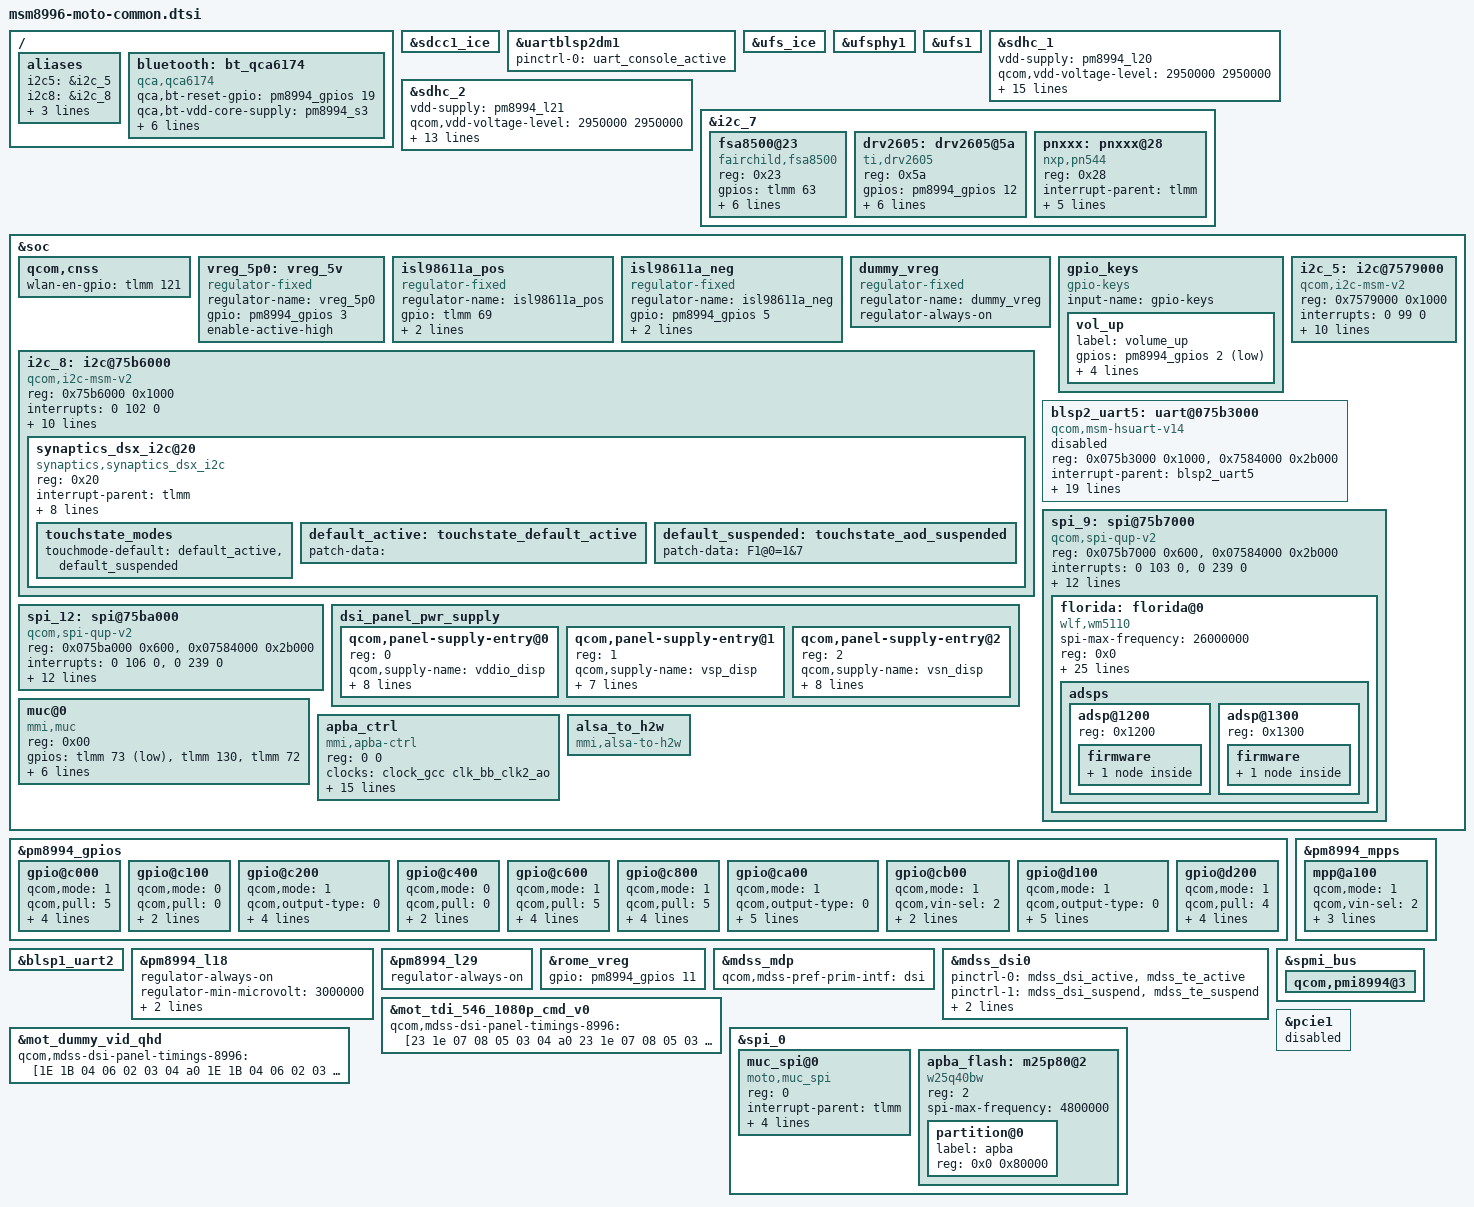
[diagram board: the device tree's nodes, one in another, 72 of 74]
/* Copyright (c) 2015, Motorola Mobility Inc. All rights reserved.
 *
 * This program is free software; you can redistribute it and/or modify
 * it under the terms of the GNU General Public License version 2 and
 * only version 2 as published by the Free Software Foundation.
 *
 * This program is distributed in the hope that it will be useful,
 * but WITHOUT ANY WARRANTY; without even the implied warranty of
 * MERCHANTABILITY or FITNESS FOR A PARTICULAR PURPOSE.  See the
 * GNU General Public License for more details.
 */


#include "msm8996-v2.dtsi"
#include "msm8996-pinctrl.dtsi"
#include "msm8996-moto-pinctrl.dtsi"

&sdcc1_ice {
        status = "ok";
};

/ {
	aliases {
		/delete-property/ i2c12;
		i2c5 = &i2c_5;
		i2c8 = &i2c_8;
		spi9 = &spi_9;
		spi12 = &spi_12;
		uart0 = &blsp1_uart2;
	};
};

&uartblsp2dm1 {
	status = "ok";
	pinctrl-names = "default";
	pinctrl-0 = <&uart_console_active>;
};

&ufs_ice {
	status = "ok";
};

&ufsphy1 {
	status = "ok";
};

&ufs1 {
	status = "ok";
};

&sdhc_1 {
	vdd-supply = <&pm8994_l20>;
	qcom,vdd-voltage-level = <2950000 2950000>;
	qcom,vdd-current-level = <200 570000>;

	vdd-io-supply = <&pm8994_s4>;
	qcom,vdd-io-always-on;
	qcom,vdd-io-voltage-level = <1800000 1800000>;
	qcom,vdd-io-current-level = <110 325000>;

	pinctrl-names = "active", "sleep";
	pinctrl-0 = <&sdc1_clk_on &sdc1_cmd_on &sdc1_data_on &sdc1_rclk_on>;
	pinctrl-1 = <&sdc1_clk_off &sdc1_cmd_off &sdc1_data_off &sdc1_rclk_off>;

	qcom,clk-rates = <400000 20000000 25000000 50000000 96000000 192000000 384000000>;
	qcom,ice-clk-rates = <300000000>;
	qcom,nonremovable;
	qcom,bus-speed-mode = "HS400_1p8v", "HS200_1p8v", "DDR_1p8v";

	status = "ok";
};

&sdhc_2 {
	vdd-supply = <&pm8994_l21>;
	qcom,vdd-voltage-level = <2950000 2950000>;
	qcom,vdd-current-level = <200 800000>;

	vdd-io-supply = <&pm8994_l13>;
	qcom,vdd-io-voltage-level = <1800000 2950000>;
	qcom,vdd-io-current-level = <200 22000>;

	pinctrl-names = "active", "sleep";
	pinctrl-0 = <&sdc2_clk_on  &sdc2_cmd_on &sdc2_data_on &sdc2_cd_on>;
	pinctrl-1 = <&sdc2_clk_off &sdc2_cmd_off &sdc2_data_off &sdc2_cd_off>;

	qcom,clk-rates = <400000 20000000 25000000 50000000 100000000 200000000>;
	qcom,bus-speed-mode = "SDR12", "SDR25", "SDR50", "DDR50", "SDR104";

	cd-gpios = <&tlmm 95 0x1>;

	status = "ok";
};

&i2c_7 {
	fsa8500@23 {
		compatible = "fairchild,fsa8500";
		reg = <0x23>;
		gpios = <&tlmm 63 0x0>;
		fsa8500-init-regs = <0x0c 0x41>,
				    <0x0f 0xf9>,
				    <0x11 0x84>,
				    <0x13 0xbf>,
				    <0x14 0x69>;

		fsa8500-keymap = <0x4000000 0xe2>, /* SND_JACK_BTN_0 - KEY_MEDIA */
				 <0x0400000 0x246>, /* SND_JACK_BTN_4 - KEY_VOICECOMMAND */
				 <0x0200000 0x73>, /* SND_JACK_BTN_5 - KEY_VOLUMEUP */
				 <0x0100000 0x72>; /* SND_JACK_BTN_6 - KEY_VOLUMEDOWN */

		pinctrl-names = "default";
		pinctrl-0 = <&fsa8500_hs_det_default>;
	};

	drv2605: drv2605@5a {
		compatible = "ti,drv2605";
		reg = <0x5a>;
		gpios = <&pm8994_gpios 12 0>;   /* EN_GPIO */
		external_trigger = <1>;         /* Enable ext. trigger */
		default_effect = <4>;           /* Sharp Click 100% */
		rated_voltage = <0x72>;         /* 2.4v */
		overdrive_voltage = <0xd1>;     /* 4.6v */
		rtp_overdrive_voltage = <0xea>; /* 4.991v */
		static-vdd-supply = <&vreg_5p0>;
	};

	pnxxx: pnxxx@28 {
		compatible = "nxp,pn544";
		reg = <0x28>;
		interrupt-parent = <&tlmm>;
		interrupts = <9 0>;
		gpios = <&tlmm 9 0>,     /* IRQ */
		    <&pm8994_gpios 9 0>,  /* VEN */
		    <&tlmm 12 0>;  /* Firmware */

		nxp,pnxxx-discharge-delay = <2000>;
		nxp,pnxxx-ven-inv-polarity = <0>;


		pinctrl-names = "default";
		pinctrl-0 = <&nfc_irq_default &nfc_firm_default>;
	};
};

&soc {
	qcom,cnss {
		/delete-property/ wlan-bootstrap-gpio; /* Pulled high with S4 */
		wlan-en-gpio = <&tlmm 121 0>;
	};

	vreg_5p0: vreg_5v {
		compatible = "regulator-fixed";
		regulator-name = "vreg_5p0";
		gpio = <&pm8994_gpios 3 0>;
		enable-active-high;
	};

	isl98611a_pos: isl98611a_pos {
		compatible = "regulator-fixed";
		regulator-name = "isl98611a_pos";
		gpio = <&tlmm 69 0>;
		startup-delay-us = <300>;
		enable-active-high;
	};

	isl98611a_neg: isl98611a_neg {
		compatible = "regulator-fixed";
		regulator-name = "isl98611a_neg";
		gpio = <&pm8994_gpios 5 0>;
		startup-delay-us = <300>;
		enable-active-high;
	};

	dummy_vreg: dummy_vreg {
		compatible = "regulator-fixed";
		status = "ok";
		regulator-name = "dummy_vreg";
		regulator-always-on;
	};
	/* BLSP12 not used for i2c */
	/delete-node/ i2c@75ba000;

	gpio_keys {
		compatible = "gpio-keys";
		input-name = "gpio-keys";

		vol_up {
			label = "volume_up";
			gpios = <&pm8994_gpios 2 0x1>;
			linux,input-type = <1>;
			linux,code = <115>;
			gpio-key,wakeup;
			debounce-interval = <15>;
		};
	};

	/* SensorHub Bus */
	i2c_5: i2c@7579000 { /* BLSP1 QUP5 */
		compatible = "qcom,i2c-msm-v2";
		#address-cells = <1>;
		#size-cells = <0>;
		reg-names = "qup_phys_addr";
		reg = <0x7579000 0x1000>;
		interrupt-names = "qup_irq";
		interrupts = <0 99 0>;
		dmas = <&dma_blsp2 20 32 0x20000020 0x20>,
			<&dma_blsp2 21 32 0x20000020 0x20>;
		dma-names = "tx", "rx";
		qcom,master-id = <86>;
		qcom,clk-freq-out = <400000>;
		qcom,clk-freq-in  = <19200000>;
		clock-names = "iface_clk", "core_clk";
		clocks = <&clock_gcc clk_gcc_blsp1_ahb_clk>,
			 <&clock_gcc clk_gcc_blsp1_qup5_i2c_apps_clk>;
		pinctrl-names = "i2c_active", "i2c_sleep";
		pinctrl-0 = <&i2c_5_active>;
		pinctrl-1 = <&i2c_5_sleep>;
		qcom,disable-dma;
	};

	/* Touchscreen bus */
	i2c_8: i2c@75b6000 { /* BLSP2 QUP2 */
		compatible = "qcom,i2c-msm-v2";
		#address-cells = <1>;
		#size-cells = <0>;
		reg-names = "qup_phys_addr";
		reg = <0x75b6000 0x1000>;
		interrupt-names = "qup_irq";
		interrupts = <0 102 0>;
		dmas = <&dma_blsp2 14 32 0x20000020 0x20>,
			<&dma_blsp2 15 32 0x20000020 0x20>;
		dma-names = "tx", "rx";
		qcom,master-id = <84>;
		qcom,clk-freq-out = <400000>;
		qcom,clk-freq-in  = <19200000>;
		clock-names = "iface_clk", "core_clk";
		clocks = <&clock_gcc clk_gcc_blsp2_ahb_clk>,
			 <&clock_gcc clk_gcc_blsp2_qup2_i2c_apps_clk>;
		pinctrl-names = "i2c_active", "i2c_sleep";
		pinctrl-0 = <&i2c_8_active>;
		pinctrl-1 = <&i2c_8_sleep>;
		qcom,disable-dma;
	};

	blsp2_uart5: uart@075b3000 { /* BLSP2 UART5 */
		compatible = "qcom,msm-hsuart-v14";
		reg = <0x075b3000 0x1000>,
		    <0x7584000 0x2b000>;
		status = "disabled";
		reg-names = "core_mem", "bam_mem";
		interrupt-names = "core_irq", "bam_irq", "wakeup_irq";
		#address-cells = <0>;
		interrupt-parent = <&blsp2_uart5>;
		interrupts = <0 1 2>;
		#interrupt-cells = <1>;
		interrupt-map-mask = <0xffffffff>;
		interrupt-map = <0 &intc 0 117 0
			    1 &intc 0 239 0
			    2 &tlmm 59 0>;

		qcom,inject-rx-on-wakeup;
		qcom,rx-char-to-inject = <0xFD>;

		qcom,bam-tx-ep-pipe-index = <8>;
		qcom,bam-rx-ep-pipe-index = <9>;
		qcom,master-id = <84>;
		clock-names = "core_clk", "iface_clk";
		clocks = <&clock_gcc clk_gcc_blsp2_uart5_apps_clk>,
		    <&clock_gcc clk_gcc_blsp2_ahb_clk>;
		pinctrl-names = "sleep", "default";
		pinctrl-0 = <&blsp2_uart5_sleep>;
		pinctrl-1 = <&blsp2_uart5_active>;

		qcom,msm-bus,name = "buart11";
		qcom,msm-bus,num-cases = <2>;
		qcom,msm-bus,num-paths = <1>;
		qcom,msm-bus,vectors-KBps =
			    <84 512 0 0>,
			    <84 512 500 800>;
	};

	spi_9: spi@75b7000 { /* BLSP2 QUP3 */
		compatible = "qcom,spi-qup-v2";
		#address-cells = <1>;
		#size-cells = <0>;
		reg-names = "spi_physical", "spi_bam_physical";
		reg = <0x075b7000 0x600>,
		      <0x07584000 0x2b000>;
		interrupt-names = "spi_irq", "spi_bam_irq";
		interrupts = <0 103 0>, <0 239 0>;
		spi-max-frequency = <48000000>;

		qcom,infinite-mode = <0>;
		qcom,use-bam;
		qcom,ver-reg-exists;
		qcom,bam-consumer-pipe-index = <12>;
		qcom,bam-producer-pipe-index = <13>;
		qcom,master-id = <84>;
		qcom,use-pinctrl;
		pinctrl-names = "spi_default", "spi_sleep";
		pinctrl-0 = <&spi_9_active>;
		pinctrl-1 = <&spi_9_sleep>;

		clock-names = "iface_clk", "core_clk";

		clocks = <&clock_gcc clk_gcc_blsp2_ahb_clk>,
			 <&clock_gcc clk_gcc_blsp2_qup3_spi_apps_clk>;
	};

	spi_12: spi@75ba000 { /* BLSP2 QUP6 */
		compatible = "qcom,spi-qup-v2";
		#address-cells = <1>;
		#size-cells = <0>;
		reg-names = "spi_physical", "spi_bam_physical";
		reg = <0x075ba000 0x600>,
		      <0x07584000 0x2b000>;
		interrupt-names = "spi_irq", "spi_bam_irq";
		interrupts = <0 106 0>, <0 239 0>;
		spi-max-frequency = <19200000>;

		qcom,infinite-mode = <0>;
		qcom,use-bam;
		qcom,ver-reg-exists;
		qcom,bam-consumer-pipe-index = <22>;
		qcom,bam-producer-pipe-index = <23>;
		qcom,master-id = <84>;
		qcom,use-pinctrl;
		pinctrl-names = "spi_default", "spi_sleep";
		pinctrl-0 = <&spi_12_active>;
		pinctrl-1 = <&spi_12_sleep>;

		clock-names = "iface_clk", "core_clk";

		clocks = <&clock_gcc clk_gcc_blsp2_ahb_clk>,
			 <&clock_gcc clk_gcc_blsp2_qup6_spi_apps_clk>;
	};

	dsi_panel_pwr_supply: dsi_panel_pwr_supply {
		#address-cells = <1>;
		#size-cells = <0>;

		qcom,panel-supply-entry@0 {
			reg = <0>;
			qcom,supply-name = "vddio_disp";
			qcom,supply-min-voltage = <1800000>;
			qcom,supply-max-voltage = <1800000>;
			qcom,supply-enable-load = <300000>;
			qcom,supply-disable-load = <100>;
			qcom,supply-pre-on-sleep = <0>;
			qcom,supply-post-on-sleep = <1>;
			qcom,supply-pre-off-sleep = <0>;
			qcom,supply-post-off-sleep = <1>;
		};

		qcom,panel-supply-entry@1 {
			reg = <1>;
			qcom,supply-name = "vsp_disp";
			qcom,supply-min-voltage = <5500000>;
			qcom,supply-max-voltage = <5500000>;
			qcom,supply-enable-load = <100000>;
			qcom,supply-disable-load = <100>;
			qcom,supply-pre-on-sleep = <0>;
			qcom,supply-post-on-sleep = <2>;
			qcom,supply-pre-off-sleep = <0>;
		};

		qcom,panel-supply-entry@2 {
			reg = <2>;
			qcom,supply-name = "vsn_disp";
			qcom,supply-min-voltage = <5500000>;
			qcom,supply-max-voltage = <5500000>;
			qcom,supply-enable-load = <100000>;
			qcom,supply-disable-load = <100>;
			qcom,supply-pre-on-sleep = <0>;
			qcom,supply-post-on-sleep = <2>;
			qcom,supply-pre-off-sleep = <0>;
			qcom,supply-post-off-sleep = <1>;
		};
	};

	muc@0 {
		compatible = "mmi,muc";
		reg = <0x00>;

		gpios = <&tlmm 73 1>,   /* gpio_muc_det_n,    input */
		        <&tlmm 130 0>,  /* gpio_muc_bplus_en, output-low */
		        <&tlmm 72 0>;   /* gpio_muc_vbus_en,  output-low */
		mmi,muc-ctrl-gpio-labels = "gpio_muc_det_n",
					"gpio_muc_bplus_en",
					"gpio_muc_vbus_en";

		mmi,muc-ctrl-det-hysteresis = <500>;
		mmi,muc-ctrl-en-seq = <1 0 200>, <1 1 300>;
		mmi,muc-ctrl-dis-seq = <1 0 200>;

		pinctrl-names = "default";
		pinctrl-0 = <&muc_attach>;
    };

	apba_ctrl {
		compatible = "mmi,apba-ctrl";
		reg = <0 0>;
		clock-names = "apba_mclk";
		clocks = <&clock_gcc clk_bb_clk2_ao>;
		pinctrl-names = "default";
		pinctrl-0 = <&apba_default>;
		gpios = <&pm8994_gpios 7 2>, /* APBA_1P1_EN, output-high */
			<&pm8994_gpios 1 2>, /* APBA_SFLASH_EN, output-high */
			<&tlmm 27 0>,        /* APBA_BOOTRET, output-low */
			<&pm8994_mpps 2 0>,  /* MOD_MPHY_I2S_EN_N, output-low */
			<&tlmm 81 0>,        /* MOD_MPHY_I2S_SEL, output-low */
			<&tlmm 131 0>,       /* APBA_RESET_N, output-low */
			<&tlmm 132 1>,       /* APBA_INT_N, in */
			<&tlmm 25 2>;        /* APBA_WAKE, output-high */
		mmi,gpio-labels = "gpio_apba_1p1_en",
				  "gpio_apba_sflash_en",
				  "gpio_apba_bootret",
				  "gpio_mphy_i2s_en_n",
				  "gpio_mphy_i2s_sel",
				  "gpio_apba_rst_n",
				  "gpio_apba_int_n",
				  "gpio_apba_wake";
		mmi,int-index = <6>;
		mmi,enable-seq = <0 1 0>, <1 0 0>, <2 0 0>, <3 0 0>, <4 0 0>, <5 0 50>, <5 1 50>;
		mmi,disable-seq = <0 1 0>, <1 1 0>, <2 0 0>, <3 0 0>, <4 1 0>, <5 0 50>;
		mmi,wake-seq = <7 0 50>, <7 1 0>;
	};

	alsa_to_h2w {
		compatible = "mmi,alsa-to-h2w";
	};
};

&pm8994_gpios {
	gpio@c000 { /* GPIO 1 - APBA_SFLASH_EN */
		qcom,mode = <1>;	/* Digital output */
		qcom,pull = <5>;	/* No Pull */
		qcom,vin-sel = <2>;	/* 1.8 */
		qcom,src-sel = <0>;	/* GPIO */
		qcom,master-en = <1>;	/* Enable GPIO */
		qcom,invert = <1>;	/* Output high (enabled) */
		status = "okay";
	};

	gpio@c100 { /* GPIO 2 - VOLUME UP */
		qcom,mode = <0>;
		qcom,pull = <0>;
		qcom,vin-sel = <2>;
		qcom,src-sel = <0>;
		status = "okay";
	};

	gpio@c200 { /* GPIO 3 - SPK_5V_BOOST_EN */
		qcom,mode = <1>;         /* QPNP_PIN_MODE_DIG_OUT */
		qcom,output-type = <0>;  /* QPNP_PIN_OUT_BUF_CMOS */
		qcom,vin-sel = <2>;      /* QPNP_PIN_VIN2 */
		qcom,src-sel = <0>;      /* QPNP_PIN_SEL_FUNC_CONSTANT */
		qcom,out-strength = <1>; /* QPNP_PIN_OUT_STRENGTH_LOW */
		qcom,master-en = <1>;
		status = "okay";
	};

	gpio@c400 { /* GPIO 5  - DISP_V2_EN */
		qcom,mode = <0>;
		qcom,pull = <0>;
		qcom,vin-sel = <2>;
		qcom,src-sel = <0>;
		status = "okay";
	};

	gpio@c600 { /* GPIO 7 - APBA_1P1_EN */
		qcom,mode = <1>;	/* Digital output */
		qcom,pull = <5>;	/* No Pull */
		qcom,vin-sel = <2>;	/* 1.8 */
		qcom,src-sel = <0>;	/* GPIO */
		qcom,master-en = <1>;	/* Enable GPIO */
		qcom,invert = <1>;	/* Output high */
		status = "okay";
	};

	gpio@c800 { /* GPIO 9 - NFC_ENABLE_N */
		status = "okay";
		qcom,mode = <1>; /* Output */
		qcom,pull = <5>; /* None */
		qcom,vin-sel = <2>;
		qcom,src-sel = <0>;
		qcom,out-strength = <1>;
		qcom,master-en = <1>;
	};

	gpio@ca00 { /* GPIO 11 - REG_3P3_ENABLE */
		qcom,mode = <1>;		/* Digital output */
		qcom,output-type = <0>;		/* MOS logic */
		qcom,invert = <1>;		/* Output high */
		qcom,vin-sel = <0>;		/* VPH_PWR */
		qcom,src-sel = <0>;		/* Constant */
		qcom,out-strength = <1>;	/* High drive strength */
		qcom,master-en = <1>;		/* Enable GPIO */
		status = "okay";
	};

	gpio@cb00 { /* GPIO 12 - AP_VIB_EN */
		qcom,mode = <1>;         /* Digital output*/
		qcom,vin-sel = <2>;      /* VIN2 */
		qcom,src-sel = <0>;      /* GPIO */
		qcom,master-en = <1>;    /* Enable GPIO */
		status = "okay";
	};

	gpio@d100 { /* GPIO 18 - Rome Sleep Clock */
		qcom,mode = <1>;		/* Digital output */
		qcom,output-type = <0>;		/* CMOS logic */
		qcom,invert = <0>;		/* Output low initially */
		qcom,vin-sel = <2>;		/* VIN 2 */
		qcom,src-sel = <3>;		/* Function 2 */
		qcom,out-strength = <2>;	/* Medium */
		qcom,master-en = <1>;		/* Enable GPIO */
		status = "okay";
	};

	gpio@d200 { /* GPIO 19 - Rome BT Reset */
		qcom,mode = <1>;		/* Digital output*/
		qcom,pull = <4>;		/* Pulldown 10uA */
		qcom,vin-sel = <2>;		/* VIN2 */
		qcom,src-sel = <0>;		/* GPIO */
		qcom,invert = <0>;		/* Invert */
		qcom,master-en = <1>;		/* Enable GPIO */
		status = "okay";
	};
};

&pm8994_mpps {
	mpp@a100 { /* MPP 2 - MOD_MPHY_I2S_EN_N */
		qcom,mode = <1>;	/* Digital output */
		qcom,vin-sel = <2>;	/* 1.8 */
		qcom,src-sel = <0>;	/* GPIO */
		qcom,master-en = <1>;	/* Enable GPIO */
		qcom,invert = <1>;	/* Output high (disabled) */
		status = "okay";
	};
};


&blsp1_uart2 {
	status = "ok";
};

&pm8994_l18 {
	regulator-always-on;
	regulator-min-microvolt = <3000000>;
	regulator-max-microvolt = <3000000>;
	qcom,init-voltage = <3000000>;
};

&pm8994_l29 {
	regulator-always-on;
};

/* 3.3V QCA Supply */
&rome_vreg {
	gpio = <&pm8994_gpios 11 0>;
};

#include "dsi-panel-mot-tdi-546-1080p-cmd.dtsi"
#include "dsi-panel-mot-dummy-qhd-video.dtsi"

&mdss_mdp {
	qcom,mdss-pref-prim-intf = "dsi";
};

&mdss_dsi0 {
	pinctrl-names = "mdss_default", "mdss_sleep";
	pinctrl-0 = <&mdss_dsi_active &mdss_te_active>;
	pinctrl-1 = <&mdss_dsi_suspend &mdss_te_suspend>;
	qcom,platform-te-gpio = <&tlmm 10 0>;
	qcom,platform-reset-gpio = <&tlmm 8 0>;
};

&mot_tdi_546_1080p_cmd_v0 {
	qcom,mdss-dsi-panel-timings-8996 = [23 1e 07 08 05 03 04 a0
			23 1e 07 08 05 03 04 a0
			23 1e 07 08 05 03 04 a0
			23 1e 07 08 05 03 04 a0
			23 18 07 08 05 03 04 a0];
};

&mot_dummy_vid_qhd {
	qcom,mdss-dsi-panel-timings-8996 = [1E 1B 04 06 02 03 04 a0
			1E 1B 04 06 02 03 04 a0
			1E 1B 04 06 02 03 04 a0
			1E 1B 04 06 02 03 04 a0
			1E 0D 04 05 02 03 04 a0];
};

/ {
	bluetooth: bt_qca6174 {
		compatible = "qca,qca6174";
		qca,bt-reset-gpio = <&pm8994_gpios 19 0>; /* BT_EN */
		qca,bt-vdd-core-supply = <&pm8994_s3>;
		qca,bt-vdd-pa-supply = <&rome_vreg>;
		qca,bt-vdd-io-supply = <&pm8994_s4>;
		qca,bt-vdd-xtal-supply = <&pm8994_l30>;
		qca,bt-chip-pwd-voltage-level = <1300000 1300000>;
		qca,bt-vdd-io-voltage-level = <1800000 1800000>;
		qca,bt-vdd-xtal-voltage-level = <1800000 1800000>;
	};
};

&spmi_bus {
	qcom,pmi8994@3 {
		/* HACK, disable PMIC LED because it keeps detected short */
		/delete-node/ qcom,leds@d800;
		/* RGB LED because it is not there*/
		/delete-node/ qcom,leds@d000;
	};
};

&spi_0 {
	muc_spi@0 {
		compatible = "moto,muc_spi";
		reg = <0>;
		interrupt-parent = <&tlmm>;
		interrupts = <26 0>;
		spi-max-frequency = <4800000>;
		gpios = <&tlmm 74 0>, /* WAKE_N */
			<&tlmm 82 0>; /* RDY_N  */

		pinctrl-names = "default";
		pinctrl-0 = <&muc_spi_ctrl>;
	};

	apba_flash: m25p80@2 {
		compatible = "w25q40bw";
		reg = <2>; /* BLSP1_SPI_CS2B_N */
		spi-max-frequency = <4800000>;

		#address-cells = <1>;
		#size-cells = <1>;
		partition@0 {
			label = "apba";
			reg = <0x0 0x80000>;
		};
	};
};

&pcie1 {
	status = "disabled";
};

&i2c_8 {
	synaptics_dsx_i2c@20 {
		compatible = "synaptics,synaptics_dsx_i2c";
		reg = <0x20>;
		interrupt-parent = <&tlmm>;
		interrupts = <40 0>;
		gpios = <&tlmm 40 0>, /* IRQ */
			<&tlmm 39 0>; /* RESET */
		touch_vdd-supply = <&pm8994_l22>;
		synaptics,gpio-config;
		pinctrl-names = "default", "active";
		pinctrl-0 = <&touch_reset_active &touch_int_default>;
		pinctrl-1 = <&touch_reset_active &touch_int_active>;
		touchstate_modes {
			touchmode-default = <&default_active &default_suspended>;
		};
		default_active: touchstate_default_active {
			patch-data = "";
		};
		default_suspended: touchstate_aod_suspended {
			patch-data = "F1@0=1&7";
		};
	};
};

&spi_9 {
	florida: florida@0 {
		compatible = "wlf,wm5110";
		spi-max-frequency = <26000000>;
		reg = <0x0>;
		interrupt-parent = <&tlmm>;
		interrupts = <54 0>;
		irq-base = <800>;
		gpio-base = <200>;
		wlf,reset = <&tlmm 64 0>;
		wlf,irq = <&tlmm 54 0>;
		wlf,out-mono = <0 1 0 0 0 0>;
		wlf,micbias1 = <1800 1 1 0 0>;
		wlf,micbias2 = <1800 1 1 0 0>;
		wlf,micbias3 = <1800 1 1 0 0>;
		wlf,vib_pwm_gpio_ctrl = <0xC02>;
		vreg-arizona1p2-supply = <&dummy_vreg>;
		pinctrl-names = "default";
		pinctrl-0 = <&florida_irq_default &florida_reset_default>;

		AVDD-supply = <&pm8994_s4>;
		DCVDD-supply = <&pm8994_s4>;
		DBVDD1-supply = <&pm8994_s4>;
		DBVDD2-supply = <&pm8994_s4>;
		DBVDD3-supply = <&pm8994_s4>;
		CPVDD-supply = <&pm8994_s4>;
		SPKVDDL-supply = <&dummy_vreg>;
		SPKVDDR-supply = <&dummy_vreg>;

		gpio-controller;
		#gpio-cells = <2>;

		wlf,gpio-defaults = <0x00002102
				0xffffffff
				0x00010000
				0x00000004
				0xffffffff>;

		adsps {
			#address-cells = <1>;
			#size-cells = <0>;
			adsp@1200 {
				reg = <0x1200>;
				firmware {
					frontend {
						wlf,wmfw-file = "aov-frontend";
						wlf,bin-file = "aov-vrgain";
						wlf,compr-caps = <1 1 4 1 16000>;
					};
				};
			};
			adsp@1300 {
				reg = <0x1300>;
				firmware {
					aov {
						wlf,wmfw-file = "aov-control";
						wlf,bin-file = "aov-model";
						wlf,compr-caps = <1 1 4 1 16000>;
					};
				};
			};
		};
	};
};

